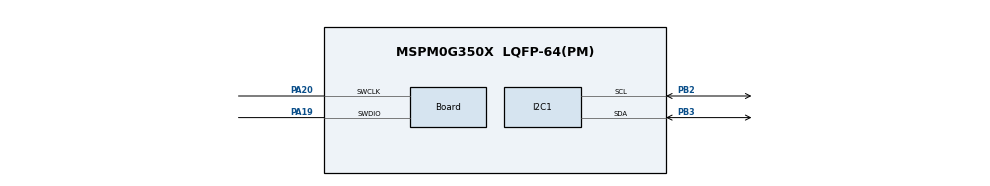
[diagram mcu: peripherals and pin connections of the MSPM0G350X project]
/**
 * @cliArgs --device "MSPM0G350X" --part "Default" --package "LQFP-64(PM)" --product "mspm0_sdk@2.02.00.05"
 * @versions {"tool":"1.21.0+3721"}
 */

/**
 * Import the modules used in this configuration.
 */
const GPIO  = scripting.addModule("/ti/driverlib/GPIO", {}, false);
const GPIO1 = GPIO.addInstance();
const GPIO2 = GPIO.addInstance();
const GPIO3 = GPIO.addInstance();
const GPIO4 = GPIO.addInstance();
const GPIO5 = GPIO.addInstance();
const GPIO6 = GPIO.addInstance();
const GPIO7 = GPIO.addInstance();
const GPIO8 = GPIO.addInstance();
const GPIO9 = GPIO.addInstance();
const I2C   = scripting.addModule("/ti/driverlib/I2C", {}, false);
const I2C1  = I2C.addInstance();

/**
 * Write custom configuration values to the imported modules.
 */
GPIO1.$name                         = "GPIO_LEDS";
GPIO1.port                          = "PORTA";
GPIO1.associatedPins[0].$name       = "USER_LED_1";
GPIO1.associatedPins[0].assignedPin = "8";

const Board                       = scripting.addModule("/ti/driverlib/Board", {}, false);
Board.peripheral.$assign          = "DEBUGSS";
Board.peripheral.swclkPin.$assign = "PA20";
Board.peripheral.swdioPin.$assign = "PA19";

GPIO2.$name                          = "GPIO_5V";
GPIO2.port                           = "PORTB";
GPIO2.associatedPins[0].$name        = "USER_5V";
GPIO2.associatedPins[0].assignedPin  = "0";
GPIO2.associatedPins[0].initialValue = "SET";

GPIO3.port                           = "PORTB";
GPIO3.$name                          = "GPIO_3_3V";
GPIO3.associatedPins[0].initialValue = "SET";
GPIO3.associatedPins[0].assignedPin  = "1";
GPIO3.associatedPins[0].$name        = "USER_3_3V";

GPIO4.$name                         = "GPIO_BL_EN";
GPIO4.port                          = "PORTA";
GPIO4.associatedPins[0].$name       = "USER_BL_EN";
GPIO4.associatedPins[0].assignedPin = "9";

GPIO5.port                          = "PORTA";
GPIO5.$name                         = "GPIO_dataPin";
GPIO5.associatedPins[0].$name       = "PIN_dataPin";
GPIO5.associatedPins[0].assignedPin = "21";

GPIO6.$name                         = "GPIO_clockPin";
GPIO6.port                          = "PORTB";
GPIO6.associatedPins[0].$name       = "PIN_clockPin";
GPIO6.associatedPins[0].assignedPin = "22";

GPIO7.port                          = "PORTB";
GPIO7.$name                         = "GPIO_latchPin";
GPIO7.associatedPins[0].$name       = "PIN_latchPin";
GPIO7.associatedPins[0].assignedPin = "21";

GPIO8.port                          = "PORTB";
GPIO8.$name                         = "GPIO_G";
GPIO8.associatedPins[0].$name       = "PIN_G";
GPIO8.associatedPins[0].assignedPin = "20";

GPIO9.$name                         = "GPIO_CLR";
GPIO9.port                          = "PORTA";
GPIO9.associatedPins[0].$name       = "PIN_CLR";
GPIO9.associatedPins[0].assignedPin = "22";

I2C1.basicEnableController             = true;
I2C1.advControllerTXFIFOTRIG           = "BYTES_1";
I2C1.intController                     = ["ARBITRATION_LOST","NACK","RXFIFO_TRIGGER","RX_DONE","TX_DONE"];
I2C1.$name                             = "I2C";
I2C1.advAnalogGlitchFilter             = "DISABLED";
I2C1.peripheral.$assign                = "I2C1";
I2C1.peripheral.sdaPin.$assign         = "PB3";
I2C1.peripheral.sclPin.$assign         = "PB2";
I2C1.sdaPinConfig.$name                = "ti_driverlib_gpio_GPIOPinGeneric0";
I2C1.sdaPinConfig.hideOutputInversion  = scripting.forceWrite(false);
I2C1.sdaPinConfig.onlyInternalResistor = scripting.forceWrite(false);
I2C1.sdaPinConfig.passedPeripheralType = scripting.forceWrite("Digital");
I2C1.sclPinConfig.$name                = "ti_driverlib_gpio_GPIOPinGeneric1";
I2C1.sclPinConfig.hideOutputInversion  = scripting.forceWrite(false);
I2C1.sclPinConfig.onlyInternalResistor = scripting.forceWrite(false);
I2C1.sclPinConfig.passedPeripheralType = scripting.forceWrite("Digital");

const SYSCTL                 = scripting.addModule("/ti/driverlib/SYSCTL", {}, false);
SYSCTL.forceDefaultClkConfig = true;
SYSCTL.clockTreeEn           = true;

/**
 * Pinmux solution for unlocked pins/peripherals. This ensures that minor changes to the automatic solver in a future
 * version of the tool will not impact the pinmux you originally saw.  These lines can be completely deleted in order to
 * re-solve from scratch.
 */
GPIO1.associatedPins[0].pin.$suggestSolution = "PA8";
GPIO2.associatedPins[0].pin.$suggestSolution = "PB0";
GPIO3.associatedPins[0].pin.$suggestSolution = "PB1";
GPIO4.associatedPins[0].pin.$suggestSolution = "PA9";
GPIO5.associatedPins[0].pin.$suggestSolution = "PA21";
GPIO6.associatedPins[0].pin.$suggestSolution = "PB22";
GPIO7.associatedPins[0].pin.$suggestSolution = "PB21";
GPIO8.associatedPins[0].pin.$suggestSolution = "PB20";
GPIO9.associatedPins[0].pin.$suggestSolution = "PA22";
